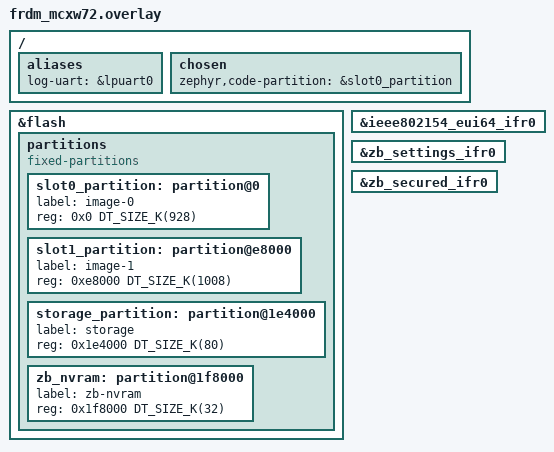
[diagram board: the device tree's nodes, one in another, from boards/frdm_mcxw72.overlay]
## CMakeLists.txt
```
# SPDX-License-Identifier: Apache-2.0

cmake_minimum_required(VERSION 3.20.0)

# Add cli feature config fragment
get_filename_component(ZBOSS_CONFIG_DIR ${CMAKE_CURRENT_SOURCE_DIR}/../../config REALPATH)
set(EXTRA_CONF_FILE ${ZBOSS_CONFIG_DIR}/add_cli.conf)

# CLI zed     : west build -b frdm_rw612 modules/zboss/samples/cli_nxp -d _build/frdm_rw612/cli_nxp_zed  -p -- -DDEVICE_TYPE=zed
# CLI zczr    : west build -b frdm_rw612 modules/zboss/samples/cli_nxp -d _build/frdm_rw612/cli_nxp_zczr -p -- -DDEVICE_TYPE=zczr
# Please note : both application can not be built at the same time in the same folder

set(DEVICE_TYPE "zed" CACHE STRING "Device type: zed or zczr")

if(DEVICE_TYPE STREQUAL "zed")
    set(OVERLAY_CONFIG ${CMAKE_CURRENT_SOURCE_DIR}/conf/zed.conf)
elseif(DEVICE_TYPE STREQUAL "zczr")
    set(OVERLAY_CONFIG ${CMAKE_CURRENT_SOURCE_DIR}/conf/zczr.conf)
else()
    message(FATAL_ERROR "Unsupported DEVICE_TYPE '${DEVICE_TYPE}' (expected 'zed' or 'zczr').")
endif()

message(STATUS "cli_nxp: building for DEVICE_TYPE '${DEVICE_TYPE}'")

find_package(Zephyr REQUIRED HINTS $ENV{ZEPHYR_BASE})
project(cli_nxp)

target_sources(app PRIVATE
	       src/cli_main.c
	       src/cli_network.c
	       src/cli_endpoint.c
	       src/cli_cluster.c
	       src/cli_zdo.c
	       src/cli_installcode.c
	       src/cli_nvram.c
	       src/cli_tcso.c
	       src/cli_tools.c
	       src/cli_config.c
	       src/cli_menu_console.c
	       )
```

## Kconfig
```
# Copyright 2024-2025 NXP
# SPDX-License-Identifier: Apache-2.0

source "Kconfig.zephyr"
module = ZBOSS_APPLICATION
module-str = zboss_main
source "${ZEPHYR_BASE}/subsys/logging/Kconfig.template.log_config"
```

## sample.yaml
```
sample:
  name: cli_nxp
  description: >
    sample application demonstrating Zigbee functionality for NXP ZBOSS stack
  common:
    min_ram: 32
    min_flash: 256
    tags: zboss
    depends_on: zboss

tests:
  sample.zboss.basic:
    tags: zboss
    harness: console
    harness_config:
      type: one_line
      regex:
        - "Zboss (.*)"
    platform_allow:
      - frdm_mcxw71
      - frdm_mcxw72
      - frdm_rw612
```

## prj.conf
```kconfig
# Zigbee Zboss Application

# OS
CONFIG_EVENTS=y
CONFIG_HEAP_MEM_POOL_SIZE=16384
CONFIG_MAIN_STACK_SIZE=6144
# Must be higher that MAC_INTF_CB_TASK_PRIORITY, refer to:
# modules/hal/nxp/mcux/middleware/mcux-sdk-middleware-ieee_802.15.4/ieee_802_15_4/mac/source/App/mac_intf_rpmsg.c
CONFIG_MAIN_THREAD_PRIORITY=5

# Enable NVMEM subsystem
CONFIG_NVMEM=y
CONFIG_NVMEM_FLASH=y
#CONFIG_LOG=y
#CONFIG_NVMEM_LOG_LEVEL_DBG=y

# Flash
CONFIG_FLASH=y
CONFIG_FLASH_MAP=y
CONFIG_FLASH_PAGE_LAYOUT=y

CONFIG_NVS=y
#CONFIG_LOG=y
#CONFIG_NVS_LOG_LEVEL_DBG=y

CONFIG_TEST_RANDOM_GENERATOR=y

CONFIG_REBOOT=y
CONFIG_ASSERT=y

CONFIG_NXP_RF_IMU=y
CONFIG_NXP_IEEE802154_MAC=y

CONFIG_DEBUG=y

CONFIG_FPU=y
CONFIG_FP_HARDABI=y

# ZBOSS module
CONFIG_ZBOSS=y
CONFIG_ZBOSS_LOGS_ON_UART=n

CONFIG_ENTROPY_GENERATOR=y
CONFIG_ENTROPY_NXP_ELE_TRNG=y

# End of common configs 
```

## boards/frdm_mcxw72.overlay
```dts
/*
 * Copyright 2026 NXP
 * SPDX-License-Identifier: Apache-2.0
 */

/ {
	aliases {
		log-uart = &lpuart0;
	};
};

/ {
	chosen {
		zephyr,code-partition = &slot0_partition;
	};
};

/* Delete all existing partitions */
/delete-node/ &boot_partition;
/delete-node/ &slot0_partition;
/delete-node/ &slot1_partition;
/delete-node/ &storage_partition;

/* Redefine internal flash partitions */
&flash {
	/delete-node/ partitions;

	partitions {
		compatible = "fixed-partitions";
		#address-cells = <1>;
		#size-cells = <1>;

		slot0_partition: partition@0 {
			label = "image-0";
			reg = <0x0 DT_SIZE_K(928)>;
		};

		/*
		 * slot1 is a bit larger than slot0 to account
		 * for the overhead introduced by SB3.1 format.
		 */
		slot1_partition: partition@e8000 {
			label = "image-1";
			reg = <0xe8000 DT_SIZE_K(1008)>;
		};

		storage_partition: partition@1e4000 {
			label = "storage";
			reg = <0x1e4000 DT_SIZE_K(80)>;
		};

		zb_nvram: partition@1f8000 {
			label = "zb-nvram";
			reg = <0x1f8000 DT_SIZE_K(32)>;
		};
	};
};

&ieee802154_eui64_ifr0 {
	status = "okay";
};

&zb_settings_ifr0 {
	status = "okay";
};

&zb_secured_ifr0 {
	status = "okay";
};
```

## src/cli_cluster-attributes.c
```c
/*
 * Copyright 2024-2026 NXP
 *
 * NXP Proprietary.
 * This software is owned or controlled by NXP and may only be used strictly
 * in accordance with the applicable license terms. By expressly accepting
 * such terms or by downloading, installing, activating and/or otherwise using
 * the software, you are agreeing that you have read, and that you agree to
 * comply with and are bound by, such license terms. If you do not agree to be
 * bound by the applicable license terms, then you may not retain, install,
 * activate or otherwise use the software.
 *
 */


static void menu_print_cluster_attributes(zb_zcl_device_callback_param_t *device_cb_params, zb_af_endpoint_desc_t *this_ep)
{
  menu_printf("Callback endpoint %u(%d clusters), attr %d, %s",
    device_cb_params->endpoint,
    (this_ep)?(this_ep->cluster_count):(0),
    device_cb_params->attr_type,
    get_device_cb_id_str(device_cb_params->device_cb_id));

}

#if defined(CLI_HAS_CLUSTER_OTA_UPGRADE_CLT) || defined(CLI_HAS_CLUSTER_OTA_UPGRADE_SRV) || defined(CLI_HAS_CLUSTER_SCENES)
static zb_bool_t is_cluster_created(zb_af_endpoint_desc_t *this_ep, zb_uint16_t cluster_id, zb_uint8_t role)
{
  if(!this_ep)
    return ZB_FALSE;

  for(int i=0; i<this_ep->cluster_count; i++)
    if(this_ep->cluster_desc_list[i].cluster_id == cluster_id &&
       this_ep->cluster_desc_list[i].role_mask & role)
      return ZB_TRUE;

  return ZB_FALSE;
}
#endif /* CLI_HAS_CLUSTER_OTA_UPGRADE_CLT || CLI_HAS_CLUSTER_OTA_UPGRADE_SRV || CLI_HAS_CLUSTER_SCENES */

void cluster_attributes_cb(zb_uint8_t param)
{
  zb_zcl_device_callback_param_t *device_cb_params = ZB_BUF_GET_PARAM(param, zb_zcl_device_callback_param_t);
  zb_af_endpoint_desc_t *this_ep = endpoint_get_by_id(device_cb_params->endpoint);

  device_cb_params->status = RET_NOT_IMPLEMENTED; //Will return ZCL status ZB_ZCL_STATUS_UNSUP_CMD
  switch(device_cb_params->device_cb_id)
  {
#ifdef CLI_HAS_CLUSTER_OTA_UPGRADE_CLT
  case ZB_ZCL_OTA_UPGRADE_VALUE_CB_ID:
    // done inside the handler... menu_print_cluster_attributes(device_cb_params, this_ep);
    /* Make sure we have created the ota cluster on client side */
    if(is_cluster_created(this_ep, ZB_ZCL_CLUSTER_ID_OTA_UPGRADE, ZB_ZCL_CLUSTER_CLIENT_ROLE))
    {
      device_cb_params->status = cluster_ota_clt_device_value_cb(device_cb_params);
    }
    else
    {
      device_cb_params->status = RET_INVALID_PARAMETER;
    }
    break;
#endif /* CLI_HAS_CLUSTER_OTA_UPGRADE_CLT */

#ifdef CLI_HAS_CLUSTER_OTA_UPGRADE_SRV
  case ZB_ZCL_OTA_UPGRADE_SRV_QUERY_IMAGE_CB_ID:
    menu_print_cluster_attributes(device_cb_params, this_ep);
    /* Make sure we have created the ota cluster on client side */
    if(is_cluster_created(this_ep, ZB_ZCL_CLUSTER_ID_OTA_UPGRADE, ZB_ZCL_CLUSTER_SERVER_ROLE))
    {
      /* Well we have already inserted files to the stack, let it manage it */
      device_cb_params->status = RET_NOT_FOUND;
    }
    else
    {
      device_cb_params->status = RET_INVALID_PARAMETER;
    }
    break;
#endif /* CLI_HAS_CLUSTER_OTA_UPGRADE_SRV */

  case ZB_ZCL_SET_ATTR_VALUE_CB_ID:
    /* This case has been added to avoid going into the default case which returns an error code, when we have a set attribute command. */
    device_cb_params->status = RET_OK;
    break;

#ifdef CLI_HAS_CLUSTER_SCENES
  case ZB_ZCL_SCENES_ADD_SCENE_CB_ID:
  case ZB_ZCL_SCENES_STORE_SCENE_CB_ID:
  case ZB_ZCL_SCENES_VIEW_SCENE_CB_ID:
  case ZB_ZCL_SCENES_REMOVE_SCENE_CB_ID:
  case ZB_ZCL_SCENES_REMOVE_ALL_SCENES_CB_ID:
  case ZB_ZCL_SCENES_RECALL_SCENE_CB_ID:
  case ZB_ZCL_SCENES_GET_SCENE_MEMBERSHIP_CB_ID:
#ifndef ZB_ZCL_SCENES_OPTIONAL_COMMANDS_DISABLED
  case ZB_ZCL_SCENES_ENHANCED_ADD_SCENE_CB_ID:
  case ZB_ZCL_SCENES_ENHANCED_VIEW_SCENE_CB_ID:
  case ZB_ZCL_SCENES_COPY_SCENE_CB_ID:
#endif /* !ZB_ZCL_SCENES_OPTIONAL_COMMANDS_DISABLED */
    if(is_cluster_created(this_ep, ZB_ZCL_CLUSTER_ID_SCENES, ZB_ZCL_CLUSTER_SERVER_ROLE))
    {
      device_cb_params->status = cluster_scenes_srv_device_value_cb(device_cb_params, param);
    }
    else
    {
      zb_uint8_t *add_scene_status = ZB_ZCL_DEVICE_CMD_PARAM_OUT_GET(param, zb_uint8_t);
      *add_scene_status = ZB_ZCL_STATUS_UNSUP_CLUST_CMD;
      device_cb_params->status = RET_NOT_IMPLEMENTED;
    }
    break;

  case ZB_ZCL_SCENES_INTERNAL_REMOVE_ALL_SCENES_ALL_ENDPOINTS_ALL_GROUPS_CB_ID:
  case ZB_ZCL_SCENES_INTERNAL_REMOVE_ALL_SCENES_ALL_ENDPOINTS_CB_ID:
    {
      /* Internal: indicate to application that it is needed to remove all scenes on all
       * endpoints for XXX groups (full reset of scenes table if XXX is all).
       */
      for(int i=0; i<256; i++)
      {
        this_ep = endpoint_get_by_id(i);
        if(!this_ep)
          continue;

        if(is_cluster_created(this_ep, ZB_ZCL_CLUSTER_ID_SCENES, ZB_ZCL_CLUSTER_SERVER_ROLE))
        {
          device_cb_params->endpoint = i;
          cluster_scenes_srv_device_value_cb(device_cb_params, param);
        }
      }
      device_cb_params->status = RET_OK;
    }
    break;
#endif /* CLI_HAS_CLUSTER_SCENES */
#ifdef CLI_HAS_CLUSTER_POLL_CONTROL
  case ZB_ZCL_POLL_CONTROL_CHECK_IN_CLI_CB_ID:
    {
      /* Enable fast polling after Check-in */
      device_cb_params->status = cluster_poll_control_device_value_cb(device_cb_params, param);
    }
    break;
#endif

  default:
    menu_print_cluster_attributes(device_cb_params, this_ep);
    break;
  }

  menu_cb_occured();
}


int wcs_snprintf_attr_raw(char *str, size_t size, zb_uint8_t type, zb_uint8_t *value)
{
  int len = 0;
  zb_uint8_t attr_len = zb_zcl_get_attribute_size(type, value);

  if(!str || !attr_len)
    return len;

  for(zb_uint8_t i=0; i<attr_len; i++)
    len += wcs_snprintf(str+len, size-len, "%02x:", value[i]);

  /* Remove last ":" */
  str[len-1] = '\0';

  return len-1;
}


typedef union {
  zb_bool_t   boolean;
  zb_uint8_t  u8;
  zb_uint16_t u16;
  zb_uint32_t u32;
  zb_uint64_t u64;
  zb_int8_t   s8;
  zb_int16_t  s16;
  zb_int32_t  s32;
  zb_int64_t  s64;
} cast_t;
#ifdef ZB_LITTLE_ENDIAN

  #define ENDIAN_24_TO_32(val8,val32) val32 = 0;                                                                            \
    val32 =              val8[3]; val32 = (val32<<8) + val8[2]; val32 = (val32<<8) + val8[1]; val32 = (val32<<8) + val8[0];

  #define ENDIAN_40_TO_64(val8,val64) val64 = 0;                                                                            \
                                                                                              val64 = (val64<<8) + val8[4]; \
    val64 = (val64<<8) + val8[3]; val64 = (val64<<8) + val8[2]; val64 = (val64<<8) + val8[1]; val64 = (val64<<8) + val8[0];

  #define ENDIAN_48_TO_64(val8,val64) val64 = 0;                                                                            \
                                                                val64 = (val64<<8) + val8[5]; val64 = (val64<<8) + val8[4]; \
    val64 = (val64<<8) + val8[3]; val64 = (val64<<8) + val8[2]; val64 = (val64<<8) + val8[1]; val64 = (val64<<8) + val8[0];

  #define ENDIAN_56_TO_64(val8,val64) val64 = 0;                                                                            \
                                  val64 = (val64<<8) + val8[6]; val64 = (val64<<8) + val8[5]; val64 = (val64<<8) + val8[4]; \
    val64 = (val64<<8) + val8[3]; val64 = (val64<<8) + val8[2]; val64 = (val64<<8) + val8[1]; val64 = (val64<<8) + val8[0];

#else

  #define ENDIAN_24_TO_32(val8,val32) val32 = 0;                                                                            \
    val32 = (val32<<8) + val8[0]; val32 = (val32<<8) + val8[1]; val32 = (val32<<8) + val8[2];

  #define ENDIAN_40_TO_64(val8,val64) val64 = 0;                                                                            \
    val64 = (val64<<8) + val8[0]; val64 = (val64<<8) + val8[1]; val64 = (val64<<8) + val8[2]; val64 = (val64<<8) + val8[3]; \
    val64 = (val64<<8) + val8[4];

  #define ENDIAN_48_TO_64(val8,val64) val64 = 0;                                                                            \
    val64 = (val64<<8) + val8[0]; val64 = (val64<<8) + val8[1]; val64 = (val64<<8) + val8[2]; val64 = (val64<<8) + val8[3]; \
    val64 = (val64<<8) + val8[4]; val64 = (val64<<8) + val8[5];

  #define ENDIAN_56_TO_64(val8,val64) val64 = 0;                                                                            \
    val64 = (val64<<8) + val8[0]; val64 = (val64<<8) + val8[1]; val64 = (val64<<8) + val8[2]; val64 = (val64<<8) + val8[3]; \
    val64 = (val64<<8) + val8[4]; val64 = (val64<<8) + val8[5]; val64 = (val64<<8) + val8[6];

#endif

int wcs_snprintf_attr_val(char *str, size_t size, zb_uint8_t type, zb_uint8_t *value)
{
  int len = 0;
  zb_uint8_t attr_len = zb_zcl_get_attribute_size(type, value);
  cast_t *cast_val = (cast_t *)value;
  cast_t data_val;

  if(!str)
    return len;

  switch(type) {
  case ZB_ZCL_ATTR_TYPE_NULL:              /*!<  0x00U: Null data type */
    len += wcs_snprintf(str+len, size-len, "NULL ");
    break;
  case ZB_ZCL_ATTR_TYPE_BOOL:              /*!<  0x10U: Boolean data type */
    len += wcs_snprintf(str+len, size-len, "%s ", (cast_val->boolean)?("true"):("false"));
    break;
  case ZB_ZCL_ATTR_TYPE_8BIT:              /*!<  0x08U: 8-bit value data type */
  case ZB_ZCL_ATTR_TYPE_8BITMAP:           /*!<  0x18U: 8-bit bitmap data type */
    len += wcs_snprintf(str+len, size-len, "0x%02x ", cast_val->u8);
    break;
  case ZB_ZCL_ATTR_TYPE_U8:                /*!<  0x20U: Unsigned 8-bit value data type */
  case ZB_ZCL_ATTR_TYPE_8BIT_ENUM:         /*!<  0x30U: 8-bit enumeration (U8 discrete) data type */
    len += wcs_snprintf(str+len, size-len, "%hhu ", cast_val->u8);
    break;
  case ZB_ZCL_ATTR_TYPE_S8:                /*!<  0x28U: Signed 8-bit value data type */
    len += wcs_snprintf(str+len, size-len, "%hhd ", cast_val->s8);
    break;
  case ZB_ZCL_ATTR_TYPE_16BIT:             /*!<  0x09U: 16-bit value data type */
  case ZB_ZCL_ATTR_TYPE_16BITMAP:          /*!<  0x19U: 16-bit bitmap data type */
    len += wcs_snprintf(str+len, size-len, "0x%04x ", cast_val->u16);
    break;
  case ZB_ZCL_ATTR_TYPE_U16:               /*!<  0x21U: Unsigned 16-bit value data type */
  case ZB_ZCL_ATTR_TYPE_16BIT_ENUM:        /*!<  0x31U: 16-bit enumeration (U16 discrete) data type */
    len += wcs_snprintf(str+len, size-len, "%hu ", cast_val->u16);
    break;
  case ZB_ZCL_ATTR_TYPE_S16:               /*!<  0x29U: Signed 16-bit value data type */
    len += wcs_snprintf(str+len, size-len, "%hd ", cast_val->s16);
    break;
  case ZB_ZCL_ATTR_TYPE_24BIT:             /*!<  0x0aU: 24-bit value data type */
  case ZB_ZCL_ATTR_TYPE_24BITMAP:          /*!<  0x1aU: 24-bit bitmap data type */
    ENDIAN_24_TO_32(value, data_val.u32);
    len += wcs_snprintf(str+len, size-len, "0x%06x ", data_val.u32);
    break;
  case ZB_ZCL_ATTR_TYPE_U24:               /*!<  0x22U: Unsigned 24-bit value data type */
    ENDIAN_24_TO_32(value, data_val.u32);
    len += wcs_snprintf(str+len, size-len, "%hu ", data_val.u32);
    break;
// TODO  case ZB_ZCL_ATTR_TYPE_S24:               /*!<  0x2aU: Signed 24-bit value data type */
    break;
  case ZB_ZCL_ATTR_TYPE_32BIT:             /*!<  0x0bU: 32-bit value data type */
  case ZB_ZCL_ATTR_TYPE_32BITMAP:          /*!<  0x1bU: 32-bit bitmap data type */
    len += wcs_snprintf(str+len, size-len, "0x%08x ", cast_val->u32);
    break;
  case ZB_ZCL_ATTR_TYPE_U32:               /*!<  0x23U: Unsigned 32-bit value data type */
    len += wcs_snprintf(str+len, size-len, "%u ", cast_val->u32);
    break;
  case ZB_ZCL_ATTR_TYPE_S32:               /*!<  0x2bU: Signed 32-bit value data type */
    len += wcs_snprintf(str+len, size-len, "%d ", cast_val->s32);
    break;
  case ZB_ZCL_ATTR_TYPE_40BIT:             /*!<  0x0cU: 40-bit value data type */
  case ZB_ZCL_ATTR_TYPE_40BITMAP:          /*!<  0x1cU: 40-bit bitmap data type */
    ENDIAN_40_TO_64(value, data_val.u64);
    len += wcs_snprintf(str+len, size-len, "0x%10lx ", data_val.u64);
    break;
  case ZB_ZCL_ATTR_TYPE_U40:               /*!<  0x24U: Unsigned 40-bit value data type */
    ENDIAN_40_TO_64(value, data_val.u64);
    len += wcs_snprintf(str+len, size-len, "%lu ", data_val.u64);
    break;
// TODO  case ZB_ZCL_ATTR_TYPE_S40:               /*!<  0x2cU: Signed 40-bit value data type */
    break;
  case ZB_ZCL_ATTR_TYPE_48BIT:             /*!<  0x0dU: 48-bit value data type */
  case ZB_ZCL_ATTR_TYPE_48BITMAP:          /*!<  0x1dU: 48-bit bitmap data type */
    ENDIAN_48_TO_64(value, data_val.u64);
    len += wcs_snprintf(str+len, size-len, "0x%12lx ", data_val.u64);
    break;
  case ZB_ZCL_ATTR_TYPE_U48:               /*!<  0x25U: Unsigned 48-bit value data type */
    ENDIAN_48_TO_64(value, data_val.u64);
    len += wcs_snprintf(str+len, size-len, "%lu ", data_val.u64);
    break;
// TODO  case ZB_ZCL_ATTR_TYPE_S48:               /*!<  0x2dU: Signed 48-bit value data type */
    break;
  case ZB_ZCL_ATTR_TYPE_56BIT:             /*!<  0x0eU: 56-bit value data type */
  case ZB_ZCL_ATTR_TYPE_56BITMAP:          /*!<  0x1eU: 56-bit bitmap data type */
    ENDIAN_56_TO_64(value, data_val.u64);
    len += wcs_snprintf(str+len, size-len, "0x%14lx ", data_val.u64);
    break;
  case ZB_ZCL_ATTR_TYPE_U56:               /*!<  0x26U: Unsigned 56-bit value data type */
    ENDIAN_56_TO_64(value, data_val.u64);
    len += wcs_snprintf(str+len, size-len, "%lu ", data_val.u64);
    break;
// TODO  case ZB_ZCL_ATTR_TYPE_S56:               /*!<  0x2eU: Signed 56-bit value data type */
    break;
  case ZB_ZCL_ATTR_TYPE_64BIT:             /*!<  0x0fU: 64-bit value data type */
  case ZB_ZCL_ATTR_TYPE_64BITMAP:          /*!<  0x1fU: 64-bit bitmap data type */
    len += wcs_snprintf(str+len, size-len, "0x%16lx ", cast_val->u64);
    break;
  case ZB_ZCL_ATTR_TYPE_U64:               /*!<  0x27U: Unsigned 64-bit value data type */
    len += wcs_snprintf(str+len, size-len, "%lu ", cast_val->u64);
    break;
  case ZB_ZCL_ATTR_TYPE_S64:               /*!<  0x2bU: Signed 32-bit value data type */
    len += wcs_snprintf(str+len, size-len, "%ld ", cast_val->s64);
    break;

// TODO  case ZB_ZCL_ATTR_TYPE_SEMI:              /*!<  0x38U: 2 byte floating point */
    break;
// TODO  case ZB_ZCL_ATTR_TYPE_SINGLE:            /*!<  0x39U: 4 byte floating point */
    break;
// TODO  case ZB_ZCL_ATTR_TYPE_DOUBLE:            /*!<  0x3aU: 8 byte floating point */
    break;
// TODO  case ZB_ZCL_ATTR_TYPE_OCTET_STRING:      /*!<  0x41U: Octet string data type */
    break;
  case ZB_ZCL_ATTR_TYPE_CHAR_STRING:       /*!<  0x42U: Character string (array) data type */
    for(int i=1; i<value[0]; i++)
      len += wcs_snprintf(str+len, size-len, "%c", value[i]);
    len += wcs_snprintf(str+len, size-len, " ");
    break;
// TODO  case ZB_ZCL_ATTR_TYPE_LONG_OCTET_STRING: /*!<  0x43U: Long octet string */
    break;
// TODO  case ZB_ZCL_ATTR_TYPE_LONG_CHAR_STRING:  /*!<  0x44U: Long character string */
    break;
// TODO  case ZB_ZCL_ATTR_TYPE_ARRAY:             /*!<  0x48U: Array data type 2 + sum of content len */
    break;
// TODO  case ZB_ZCL_ATTR_TYPE_STRUCTURE:         /*!<  0x4cU: Structure data type 2 + sum of content len */
    break;
// TODO  case ZB_ZCL_ATTR_TYPE_SET:               /*!<  0x50U: Collection:set, size = sum of len of content */
    break;
// TODO  case ZB_ZCL_ATTR_TYPE_BAG:               /*!<  0x51U: Collection:bag, size = sum of len of content */
    break;
  case ZB_ZCL_ATTR_TYPE_TIME_OF_DAY:       /*!<  0xe0U: Time of day, 4 bytes */
    len += wcs_snprintf(str+len, size-len, "0x%08x ", cast_val->u32);
    break;
  case ZB_ZCL_ATTR_TYPE_DATE:              /*!<  0xe1U: Date, 4 bytes */
    len += wcs_snprintf(str+len, size-len, "0x%08x ", cast_val->u32);
    break;
  case ZB_ZCL_ATTR_TYPE_UTC_TIME:          /*!<  0xe2U: UTC Time, 4 bytes */
    len += wcs_snprintf(str+len, size-len, "0x%08x ", cast_val->u32);
    break;
  case ZB_ZCL_ATTR_TYPE_CLUSTER_ID:        /*!<  0xe8U: Cluster ID, 2 bytes */
    len += wcs_snprintf(str+len, size-len, "0x%04x ", cast_val->u16);
    break;
  case ZB_ZCL_ATTR_TYPE_ATTRIBUTE_ID:      /*!<  0xe9U: Attribute ID, 2 bytes */
    len += wcs_snprintf(str+len, size-len, "0x%04x ", cast_val->u16);
    break;
  case ZB_ZCL_ATTR_TYPE_BACNET_OID:        /*!<  0xeaU: BACnet OID, 4 bytes */
    len += wcs_snprintf(str+len, size-len, "0x%08x ", cast_val->u32);
    break;
  case ZB_ZCL_ATTR_TYPE_IEEE_ADDR:
    len += wcs_snprintf(str+len, size-len, TRACE_FORMAT_64, TRACE_ARG_64(value));
    break;
  case ZB_ZCL_ATTR_TYPE_128_BIT_KEY:
    len += wcs_snprintf(str+len, size-len, TRACE_FORMAT_128, TRACE_ARG_128(value));
    break;

  default:
    len += wcs_snprintf(str+len, size-len, "Type:0x%02x,Len:%u", type, attr_len);
    break;
  }
  return len;
}
```

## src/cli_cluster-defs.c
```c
/*
 * Copyright 2024-2026 NXP
 *
 * NXP Proprietary.
 * This software is owned or controlled by NXP and may only be used strictly
 * in accordance with the applicable license terms. By expressly accepting
 * such terms or by downloading, installing, activating and/or otherwise using
 * the software, you are agreeing that you have read, and that you agree to
 * comply with and are bound by, such license terms. If you do not agree to be
 * bound by the applicable license terms, then you may not retain, install,
 * activate or otherwise use the software.
 *
 */


#ifdef CLI_HAS_CLUSTER_BASIC
/* -----------------------------------------------------------------------------------
 *
 *                                  CLUSTER Basic
 *
 * ----------------------------------------------------------------------------------- */

/* Basic cluster attributes */
typedef struct {
  /* ZCL version attribute */
  zb_uint8_t zcl_version;
  /* Power source attribute */
  zb_uint8_t power_source;
} zb_zcl_general_basic_attr_t;

static zb_zcl_general_basic_attr_t g_general_basic_attr = {
  .zcl_version  = ZB_ZCL_VERSION,
  .power_source = ZB_ZCL_BASIC_POWER_SOURCE_UNKNOWN,
};
#endif /* CLI_HAS_CLUSTER_BASIC */

/* -----------------------------------------------------------------------------------
 *
 *                                  CLUSTER Power Configuration
 *
 * ----------------------------------------------------------------------------------- */


/* -----------------------------------------------------------------------------------
 *
 *                                  CLUSTER Device Temperature Configuration
 *
 * ----------------------------------------------------------------------------------- */


#ifdef CLI_HAS_CLUSTER_IDENTITY
/* -----------------------------------------------------------------------------------
 *
 *                                  CLUSTER Identify
 *
 * ----------------------------------------------------------------------------------- */

/* Identify cluster attributes */
typedef struct {
  zb_uint16_t identify_time;
} zb_zcl_general_identity_attr_t;

static zb_zcl_general_identity_attr_t g_general_identity_attr = {
  .identify_time = ZB_ZCL_IDENTIFY_IDENTIFY_TIME_DEFAULT_VALUE,
};
#endif /* CLI_HAS_CLUSTER_IDENTITY */


#ifdef CLI_HAS_CLUSTER_GROUPS
/* -----------------------------------------------------------------------------------
 *
 *                                  CLUSTER Groups
 *
 * ----------------------------------------------------------------------------------- */

/* Groups cluster attributes */
typedef struct {
  zb_uint8_t name_support;
} zb_zcl_general_groups_attr_t;

static zb_zcl_general_groups_attr_t g_general_groups_attr = {
  .name_support = 0,
};
#endif /* CLI_HAS_CLUSTER_GROUPS */


#ifdef CLI_HAS_CLUSTER_SCENES
/* -----------------------------------------------------------------------------------
 *
 *                                  CLUSTER Scenes
 *
 * ----------------------------------------------------------------------------------- */

/* Scenes cluster attributes */
typedef struct {
  zb_uint8_t  scene_count;
  zb_uint8_t  current_scene;
  zb_uint16_t current_group;
  zb_uint8_t  scene_valid;
  zb_uint16_t name_support;
} zb_zcl_general_scenes_attr_t;

static zb_zcl_general_scenes_attr_t g_general_scenes_attr = {
  .scene_count   = ZB_ZCL_SCENES_SCENE_COUNT_DEFAULT_VALUE,
  .current_scene = ZB_ZCL_SCENES_CURRENT_SCENE_DEFAULT_VALUE,
  .current_group = ZB_ZCL_SCENES_CURRENT_GROUP_DEFAULT_VALUE,
  .scene_valid   = ZB_ZCL_SCENES_SCENE_VALID_DEFAULT_VALUE,
  .name_support  = ZB_ZCL_SCENES_NAME_SUPPORT_DEFAULT_VALUE,
};
#endif /* CLI_HAS_CLUSTER_SCENES */


#ifdef CLI_HAS_CLUSTER_ONOFF
/* -----------------------------------------------------------------------------------
 *
 *                                  CLUSTER ON/OFF
 *
 * ----------------------------------------------------------------------------------- */


/* On/Off cluster attributes */
typedef struct {
  zb_uint8_t on_off;
} zb_zcl_general_on_off_attr_t;

static zb_zcl_general_on_off_attr_t g_general_on_off_attr = {
  .on_off = ZB_ZCL_ON_OFF_ON_OFF_DEFAULT_VALUE,
};
#endif /* CLI_HAS_CLUSTER_ONOFF */


#ifdef CLI_HAS_CLUSTER_ONOFF_SWITCH
/* -----------------------------------------------------------------------------------
 *
 *                                  CLUSTER ON/OFF Switch Configuration
 *
 * ----------------------------------------------------------------------------------- */

/* Switch config cluster attributes */
typedef struct {
  zb_uint8_t type;
  zb_uint8_t actions;
} zb_zcl_general_on_off_switch_attr_t;

static zb_zcl_general_on_off_switch_attr_t g_general_on_off_switch_attr = {
  .type    = ZB_ZCL_ON_OFF_SWITCH_CONFIGURATION_SWITCH_TYPE_TOGGLE,
  .actions = ZB_ZCL_ON_OFF_SWITCH_CONFIGURATION_SWITCH_ACTIONS_DEFAULT_VALUE,
};
#endif /* CLI_HAS_CLUSTER_ONOFF_SWITCH */


/* -----------------------------------------------------------------------------------
 *
 *                                  CLUSTER Level Control
 *
 * ----------------------------------------------------------------------------------- */


/* -----------------------------------------------------------------------------------
 *
 *                                  CLUSTER Alarms
 *
 * ----------------------------------------------------------------------------------- */


/* -----------------------------------------------------------------------------------
 *
 *                                  CLUSTER Time
 *
 * ----------------------------------------------------------------------------------- */


/* -----------------------------------------------------------------------------------
 *
 *                                  CLUSTER RSSI Location
 *
 * ----------------------------------------------------------------------------------- */


/* -----------------------------------------------------------------------------------
 *
 *                                  CLUSTER Analog Input
 *
 * ----------------------------------------------------------------------------------- */


/* -----------------------------------------------------------------------------------
 *
 *                                  CLUSTER Analog Output
 *
 * ----------------------------------------------------------------------------------- */


/* -----------------------------------------------------------------------------------
 *
 *                                  CLUSTER Analogue Value
 *
 * ----------------------------------------------------------------------------------- */


/* -----------------------------------------------------------------------------------
 *
 *                                  CLUSTER Binary Input
 *
 * ----------------------------------------------------------------------------------- */


/* -----------------------------------------------------------------------------------
 *
 *                                  CLUSTER Binary Output
 *
 * ----------------------------------------------------------------------------------- */


/* -----------------------------------------------------------------------------------
 *
 *                                  CLUSTER Binary Value
 *
 * ----------------------------------------------------------------------------------- */


/* -----------------------------------------------------------------------------------
 *
 *                                  CLUSTER Multistate Input
 *
 * ----------------------------------------------------------------------------------- */


/* -----------------------------------------------------------------------------------
 *
 *                                  CLUSTER Multistate Output
 *
 * ----------------------------------------------------------------------------------- */


/* -----------------------------------------------------------------------------------
 *
 *                                  CLUSTER Multistate Value
 *
 * ----------------------------------------------------------------------------------- */


/* -----------------------------------------------------------------------------------
 *
 *                                  CLUSTER Diagnostics
 *
 * ----------------------------------------------------------------------------------- */


/* -----------------------------------------------------------------------------------
 *
 *                                  CLUSTER Poll Control
 *
 * ----------------------------------------------------------------------------------- */

/* Poll Control cluster attributes */

#define ZB_ZCL_POLL_CONTROL_NXP_MIN_CHECKIN_INTERVAL         0x10  /* 16 quarterseconds == 4 sec  */
#define ZB_ZCL_POLL_CONTROL_NXP_CHECKIN_INTERVAL             0x50  /* 80 quarterseconds == 20 sec */
#define ZB_ZCL_POLL_CONTROL_NXP_MIN_LONG_POLL_INTERVAL      4
#define ZB_ZCL_POLL_CONTROL_NXP_FAST_POLL_MAX_TIMEOUT_DEFAULT_VALUE 300 /* 300 quarterseconds == 75 seconds */

typedef struct zb_zcl_general_poll_control_attr_s
{
  zb_uint32_t checkin_interval;
  zb_uint32_t long_poll_interval;
  zb_uint16_t short_poll_interval;
  zb_uint16_t fast_poll_timeout;
  zb_uint32_t checkin_interval_min;
  zb_uint32_t long_poll_interval_min;
  zb_uint16_t fast_poll_timeout_max;
}
zb_zcl_general_poll_control_attr_t;

static zb_zcl_general_poll_control_attr_t g_general_poll_control_attr = {
  .checkin_interval       = ZB_ZCL_POLL_CONTROL_NXP_CHECKIN_INTERVAL,
  .long_poll_interval     = ZB_ZCL_POLL_CONTROL_LONG_POLL_INTERVAL_DEFAULT_VALUE,
  .short_poll_interval    = ZB_ZCL_POLL_CONTROL_SHORT_POLL_INTERVAL_DEFAULT_VALUE,
  .fast_poll_timeout      = ZB_ZCL_POLL_CONTROL_FAST_POLL_TIMEOUT_DEFAULT_VALUE,
  .checkin_interval_min   = ZB_ZCL_POLL_CONTROL_NXP_MIN_CHECKIN_INTERVAL,
  .long_poll_interval_min = ZB_ZCL_POLL_CONTROL_NXP_MIN_LONG_POLL_INTERVAL,
  .fast_poll_timeout_max  = ZB_ZCL_POLL_CONTROL_NXP_FAST_POLL_MAX_TIMEOUT_DEFAULT_VALUE,
};

static zb_zcl_poll_control_client_status_t pollctrl_client_status = {
  .is_poll_mode      = ZB_TRUE,
  .fast_poll_timeout = ZB_ZCL_POLL_CONTROL_FAST_POLL_TIMEOUT_DEFAULT_VALUE,
};

static zb_zcl_poll_control_srv_cfg_data_t pollctrl_srv_cfg_data = {
  .poll_addr      = ZB_ZCL_POLL_CTRL_INVALID_ADDR,
  .poll_ep        = ZB_ZCL_POLL_INVALID_EP,
  .sending_cmd    = 0,
  .fast_poll_mode = 0,
};


/* -----------------------------------------------------------------------------------
 *
 *                                  CLUSTER Power Profile
 *
 * ----------------------------------------------------------------------------------- */


/* -----------------------------------------------------------------------------------
 *
 *                                  CLUSTER Meter Identification
 *
 * ----------------------------------------------------------------------------------- */


/* -----------------------------------------------------------------------------------
 *
 *                                  CLUSTER Illuminance Measurement
 *
 * ----------------------------------------------------------------------------------- */


/* -----------------------------------------------------------------------------------
 *
 *                                  CLUSTER Illuminance Level Sensing
 *
 * ----------------------------------------------------------------------------------- */


#ifdef CLI_HAS_CLUSTER_TEMPERATURE
/* -----------------------------------------------------------------------------------
 *
 *                                  CLUSTER Temperature Measurement
 *
 * ----------------------------------------------------------------------------------- */

/* On/Off cluster attributes */
typedef struct {
  zb_int16_t value;
  zb_int16_t min_value;
  zb_int16_t max_value;
  zb_uint16_t tolerance;
} zb_zcl_measur_lvlsensor_temp_measurement_attr_t;

static zb_zcl_measur_lvlsensor_temp_measurement_attr_t g_lvlsensor_temp_measurement_attr = {
  .value = ZB_ZCL_TEMP_MEASUREMENT_VALUE_DEFAULT_VALUE,
  .min_value = ZB_ZCL_TEMP_MEASUREMENT_MIN_VALUE_DEFAULT_VALUE,
  .max_value = ZB_ZCL_TEMP_MEASUREMENT_MAX_VALUE_DEFAULT_VALUE,
#ifndef ZB_DISABLE_TEMP_MEASUREMENT_TOLERANCE_ID
  .tolerance = 0,
#endif
};
#endif /* CLI_HAS_CLUSTER_TEMPERATURE */


/* -----------------------------------------------------------------------------------
 *
 *                                  CLUSTER Pressure Measurement
 *
 * ----------------------------------------------------------------------------------- */


/* -----------------------------------------------------------------------------------
 *
 *                                  CLUSTER Flow Measurement
 *
 * ----------------------------------------------------------------------------------- */


/* -----------------------------------------------------------------------------------
 *
 *                                  CLUSTER Relative Humidity Measurement
 *
 * ----------------------------------------------------------------------------------- */


/* -----------------------------------------------------------------------------------
 *
 *                                  CLUSTER Occupancy Sensing
 *
 * ----------------------------------------------------------------------------------- */


/* -----------------------------------------------------------------------------------
 *
 *                                  CLUSTER Electrical Measurement
 *
 * ----------------------------------------------------------------------------------- */


#if defined CLI_HAS_CLUSTER_OTA_UPGRADE_SRV || defined CLI_HAS_CLUSTER_OTA_UPGRADE_CLT
/* -----------------------------------------------------------------------------------
 *
 *                                  CLUSTER OTA Upgrade
 *
 * ----------------------------------------------------------------------------------- */

/* Client config */
#define OTA_UPGRADE_DEFAULT_MANUFACTURER       0xFFFF
#define OTA_UPGRADE_DEFAULT_IMAGE_TYPE         0xFFFF

/* OTA Upgrade client cluster attributes */
typedef struct {
  /* UpgradeServerID attribute */
  zb_ieee_addr_t upgrade_server;
  /* FileOffset attribute */
  zb_uint32_t file_offset;
  /* CurrentFileVersion attribute (custom data) */
  zb_uint32_t file_version;
  /* CurrentZigbeeStackVersion attribute */
  zb_uint16_t stack_version;
  /* DownloadedFileVersion attribute */
  zb_uint32_t downloaded_file_ver;
  /* DownloadedZigbeeStackVersion attribute */
  zb_uint16_t downloaded_stack_ver;
  /* ImageUpgradeStatus attribute */
  zb_uint8_t image_status;
  /* Manufacturer ID attribute (custom data) */
  zb_uint16_t manufacturer;
  /* Image Type ID attribute (custom data) */
  zb_uint16_t image_type;
  /* MinimumBlockPeriod attribute */
  zb_uint16_t min_block_period;
  /* Image Stamp attribute */
  zb_uint16_t image_stamp;
} zb_zcl_general_ota_upgrade_attr_t;

static zb_zcl_general_ota_upgrade_attr_t g_general_ota_upgrade_attr = {
  .upgrade_server       = ZB_ZCL_OTA_UPGRADE_SERVER_DEF_VALUE,
  .file_offset          = ZB_ZCL_OTA_UPGRADE_FILE_OFFSET_DEF_VALUE,
  .file_version         = 0x00000000, /* Make sure own version is different from the server to get the file */
  .stack_version        = ZB_ZCL_OTA_UPGRADE_FILE_HEADER_STACK_PRO,
  .downloaded_file_ver  = ZB_ZCL_OTA_UPGRADE_DOWNLOADED_FILE_VERSION_DEF_VALUE,
  .downloaded_stack_ver = ZB_ZCL_OTA_UPGRADE_DOWNLOADED_STACK_DEF_VALUE,
  .image_status         = ZB_ZCL_OTA_UPGRADE_IMAGE_STATUS_DEF_VALUE,
  .manufacturer         = OTA_UPGRADE_DEFAULT_MANUFACTURER,
  .image_type           = OTA_UPGRADE_DEFAULT_IMAGE_TYPE,
  .min_block_period     = 0,
  .image_stamp          = ZB_ZCL_OTA_UPGRADE_IMAGE_STAMP_MIN_VALUE,
};

enum zb_zcl_nxp_ota_cmd_e
{
  ZB_ZCL_CMD_OTA_NXP_STATUS      = 0x00,  /* Status OTA NXP command identifier. */
  ZB_ZCL_CMD_OTA_NXP_GET_FILE    = 0x01,  /* Get file OTA NXP command identifier. */
  ZB_ZCL_CMD_OTA_NXP_ACCEPT_FILE = 0x02,  /* Accept File OTA NXP command identifier. */
#ifdef ZB_STACK_REGRESSION_TESTING_API
  ZB_ZCL_CMD_OTA_NXP_AUTO        = 0x03,  /* Auto OTA NXP command identifier. */
  ZB_ZCL_CMD_OTA_NXP_TEMPO       = 0x04,  /* Tempo OTA NXP command identifier. */
#endif
};
#endif /* CLI_HAS_CLUSTER_OTA_UPGRADE_SRV || CLI_HAS_CLUSTER_OTA_UPGRADE_CLT */


#ifdef CLI_HAS_CLUSTER_THERMOSTAT
/* -----------------------------------------------------------------------------------
 *
 *                                  CLUSTER Thermostat
 *
 * ----------------------------------------------------------------------------------- */

/* Thermostat cluster attributes */
typedef struct {
  zb_int16_t local_temperature;
  zb_int16_t occupied_cooling_setpoint;
  zb_int16_t occupied_heating_setpoint;
  zb_uint8_t control_seq_of_operation;
  zb_uint8_t system_mode;
} zb_zcl_general_thermostat_attr_t;

static zb_zcl_general_thermostat_attr_t g_general_thermostat_attr = {
  .local_temperature = ZB_ZCL_THERMOSTAT_LOCAL_TEMPERATURE_DEFAULT_VALUE,
  .occupied_cooling_setpoint = ZB_ZCL_THERMOSTAT_OCCUPIED_COOLING_SETPOINT_DEFAULT_VALUE,
  .occupied_heating_setpoint = ZB_ZCL_THERMOSTAT_OCCUPIED_HEATING_SETPOINT_DEFAULT_VALUE,
  .control_seq_of_operation  = ZB_ZCL_THERMOSTAT_CONTROL_SEQ_OF_OPERATION_DEFAULT_VALUE,
  .system_mode               = ZB_ZCL_THERMOSTAT_CONTROL_SYSTEM_MODE_DEFAULT_VALUE,
};
#endif /* CLI_HAS_CLUSTER_THERMOSTAT */


#ifdef CLI_HAS_CLUSTER_MANUF_SPE
/* -----------------------------------------------------------------------------------
 *
 *                                  CLUSTER NXP CUSTOM
 *
 * ----------------------------------------------------------------------------------- */

typedef zb_uint8_t zb_24bit_t[3];
typedef zb_uint8_t zb_40bit_t[5];
typedef zb_uint8_t zb_48bit_t[6];
typedef zb_uint8_t zb_56bit_t[7];
typedef zb_uint8_t zb_64bit_t[8];
typedef zb_uint8_t zb_128bit_t[16];
typedef struct {
  zb_uint8_t size; /* max size: 255! */
  zb_uint8_t data[256];
} zb_string_t;
typedef struct {
  zb_uint16_t size; /* max size: 255! */
  zb_uint8_t data[256];
} zb_long_string_t;
typedef struct { /* refer to zb_zcl_get_attribute_size() */
  zb_uint8_t       type_null;
  zb_uint8_t       type_8bit;
  zb_uint16_t      type_16bit;
  zb_24bit_t       type_24bit;
  zb_uint32_t      type_32bit;
  zb_40bit_t       type_40bit;
  zb_48bit_t       type_48bit;
  zb_56bit_t       type_56bit;
  zb_64bit_t       type_64bit;
  zb_bool_t        type_bool;
  zb_uint8_t       type_8bitmap;
  zb_uint16_t      type_16bitmap;
  zb_24bit_t       type_24bitmap;
  zb_uint32_t      type_32bitmap;
  zb_40bit_t       type_40bitmap;
  zb_48bit_t       type_48bitmap;
  zb_56bit_t       type_56bitmap;
  zb_64bit_t       type_64bitmap;
  zb_uint8_t       type_u8;
  zb_uint16_t      type_u16;
  zb_24bit_t       type_u24;
  zb_uint32_t      type_u32;
  zb_40bit_t       type_u40;
  zb_48bit_t       type_u48;
  zb_56bit_t       type_u56;
  zb_64bit_t       type_u64;
  zb_int8_t        type_s8;
  zb_int16_t       type_s16;
  zb_24bit_t       type_s24;
  zb_int32_t       type_s32;
  zb_40bit_t       type_s40;
  zb_48bit_t       type_s48;
  zb_56bit_t       type_s56;
  zb_64bit_t       type_s64;
  zb_uint8_t       type_8bit_enum;
  zb_uint16_t      type_16bit_enum;
  zb_uint16_t      type_semi;
  zb_uint32_t      type_single;
  zb_64bit_t       type_double;
  zb_string_t      type_octet_string;
  zb_string_t      type_char_string;
  zb_uint8_t       type_long_octet_string[256];
  zb_long_string_t type_long_char_string;
  zb_uint8_t       type_array[256];
  zb_uint8_t       type_custom_32array[256];
  zb_uint8_t       type_structure[256];
  zb_uint8_t       type_set[256];
  zb_uint8_t       type_bag[256];
  zb_uint32_t      type_time_of_day;
  zb_uint32_t      type_date;
  zb_uint32_t      type_utc_time;
  zb_uint16_t      type_cluster_id;
  zb_uint16_t      type_attribute_id;
  zb_uint32_t      type_bacnet_oid;
  zb_ieee_addr_t   type_ieee_addr;
  zb_128bit_t      type_128_bit_key;
} zb_zcl_custom_nxp_attr_access_t;

typedef struct {
  zb_zcl_custom_nxp_attr_access_t ro; /* read */
  zb_zcl_custom_nxp_attr_access_t ow; /*      write */
  zb_zcl_custom_nxp_attr_access_t rw; /* read write */
} zb_zcl_custom_nxp_attr_t;


static zb_zcl_custom_nxp_attr_t g_custom_nxp_attr = { 0 };

enum zb_zcl_nxp_custom_cmd_e
{
  ZB_ZCL_CMD_NXP_PING    = 0x01,  /* Payload NXP custom command ping identifier. */
  ZB_ZCL_CMD_NXP_ABORT   = 0x02,  /* Payload NXP custom command abort ongoing ping identifier. */
  ZB_ZCL_CMD_NXP_STATUS  = 0x03,  /* Payload NXP custom command status ongoing ping identifier. */
};
#endif /* CLI_HAS_CLUSTER_MANUF_SPE */
```

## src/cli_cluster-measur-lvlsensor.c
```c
/*
 * Copyright 2025 NXP
 *
 * NXP Proprietary.
 * This software is owned or controlled by NXP and may only be used strictly
 * in accordance with the applicable license terms. By expressly accepting
 * such terms or by downloading, installing, activating and/or otherwise using
 * the software, you are agreeing that you have read, and that you agree to
 * comply with and are bound by, such license terms. If you do not agree to be
 * bound by the applicable license terms, then you may not retain, install,
 * activate or otherwise use the software.
 *
 */


/* -----------------------------------------------------------------------------------
 *
 *                                  CLUSTER Illuminance Measurement
 *
 * ----------------------------------------------------------------------------------- */


/* -----------------------------------------------------------------------------------
 *
 *                                  CLUSTER Illuminance Level Sensing
 *
 * ----------------------------------------------------------------------------------- */


/* -----------------------------------------------------------------------------------
 *
 *                                  CLUSTER Temperature Measurement
 *
 * ----------------------------------------------------------------------------------- */
#ifndef CLI_HAS_CLUSTER_TEMPERATURE
#define pCluster_0402 NULL
#else
#define pCluster_0402 &cluster_0402

/* variable hidden  in macro ZB_ZCL_START_DECLARE_ATTRIB_LIST_CLUSTER_REVISION */
static zb_uint16_t cluster_revision_temp_measurement_attr_list = ZB_ZCL_TEMP_MEASUREMENT_CLUSTER_REVISION_DEFAULT;

/* This table is extracted from macro
 *   ZB_ZCL_DECLARE_TEMP_MEASUREMENT_ATTRIB_LIST(temp_measurement_attr_list, 
 *                                               &g_attr_temp_measurement_value, 
 *                                               &g_attr_temp_measurement_min_value, 
 *                                               &g_attr_temp_measurement_max_value, 
 *                                               &g_attr_temp_measurement_tolerance);
 * to have a better view of its content
 *     ZB_ZCL_START_DECLARE_ATTRIB_LIST_CLUSTER_REVISION(attr_list, ZB_ZCL_TEMP_MEASUREMENT)
 *     ZB_ZCL_SET_ATTR_DESC(ZB_ZCL_ATTR_TEMP_MEASUREMENT_VALUE_ID, &g_attr_temp_measurement_value)
 *     ZB_ZCL_SET_ATTR_DESC(ZB_ZCL_ATTR_TEMP_MEASUREMENT_MIN_VALUE_ID, &g_attr_temp_measurement_min_value)
 *     ZB_ZCL_SET_ATTR_DESC(ZB_ZCL_ATTR_TEMP_MEASUREMENT_MAX_VALUE_ID, &g_attr_temp_measurement_max_value)
 *     ZB_ZCL_SET_ATTR_DESC(ZB_ZCL_ATTR_TEMP_MEASUREMENT_TOLERANCE_ID, &g_attr_temp_measurement_tolerance)
 *     ZB_ZCL_FINISH_DECLARE_ATTRIB_LIST
 */

static zb_zcl_attr_t cluster_attr_0402[] = {
  /* Mandatory attributes */
  { ZB_ZCL_ATTR_GLOBAL_CLUSTER_REVISION_ID,    ZB_ZCL_ATTR_TYPE_U16, ACC_READ_ONLY,                 NO_MANUF_SPE, (void*)&cluster_revision_temp_measurement_attr_list },
  { ZB_ZCL_ATTR_TEMP_MEASUREMENT_VALUE_ID,     ZB_ZCL_ATTR_TYPE_S16, ACC_READ_ONLY | ACC_REPORTING, NO_MANUF_SPE, (void*)&g_lvlsensor_temp_measurement_attr.value },
  { ZB_ZCL_ATTR_TEMP_MEASUREMENT_MIN_VALUE_ID, ZB_ZCL_ATTR_TYPE_S16, ACC_READ_ONLY,                 NO_MANUF_SPE, (void*)&g_lvlsensor_temp_measurement_attr.min_value },
  { ZB_ZCL_ATTR_TEMP_MEASUREMENT_MAX_VALUE_ID, ZB_ZCL_ATTR_TYPE_S16, ACC_READ_ONLY,                 NO_MANUF_SPE, (void*)&g_lvlsensor_temp_measurement_attr.max_value },
#ifndef ZB_DISABLE_TEMP_MEASUREMENT_TOLERANCE_ID
  { ZB_ZCL_ATTR_TEMP_MEASUREMENT_TOLERANCE_ID, ZB_ZCL_ATTR_TYPE_U16, ACC_READ_ONLY,                 NO_MANUF_SPE, (void*)&g_lvlsensor_temp_measurement_attr.tolerance },
#endif
  /* Optional attributes */
  /* End of table */
  { ZB_ZCL_NULL_ID,                         0,                          0,             NO_MANUF_SPE, NULL }
};


static zb_cluster_def cluster_0402 = {
  cluster_attr_0402,
  sizeof(cluster_attr_0402)/sizeof(zb_zcl_attr_t),
  zb_zcl_temp_measurement_init_server,                          /* Can be replaced by our implementation to configure zb_zcl_cluster_write_attr_hook_t */
  zb_zcl_temp_measurement_init_client,                          /* Can be replaced by our implementation to configure zb_zcl_cluster_write_attr_hook_t */
  dummy_commands_handler,
};
#endif /* CLI_HAS_CLUSTER_TEMPERATURE */


/* -----------------------------------------------------------------------------------
 *
 *                                  CLUSTER Pressure Measurement
 *
 * ----------------------------------------------------------------------------------- */


/* -----------------------------------------------------------------------------------
 *
 *                                  CLUSTER Flow Measurement
 *
 * ----------------------------------------------------------------------------------- */


/* -----------------------------------------------------------------------------------
 *
 *                                  CLUSTER Relative Humidity Measurement
 *
 * ----------------------------------------------------------------------------------- */


/* -----------------------------------------------------------------------------------
 *
 *                                  CLUSTER Occupancy Sensing
 *
 * ----------------------------------------------------------------------------------- */


/* -----------------------------------------------------------------------------------
 *
 *                                  CLUSTER Electrical Measurement
 *
 * ----------------------------------------------------------------------------------- */
```

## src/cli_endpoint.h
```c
/*
 * Copyright 2024-2025 NXP
 *
 * NXP Proprietary.
 * This software is owned or controlled by NXP and may only be used strictly
 * in accordance with the applicable license terms. By expressly accepting
 * such terms or by downloading, installing, activating and/or otherwise using
 * the software, you are agreeing that you have read, and that you agree to
 * comply with and are bound by, such license terms. If you do not agree to be
 * bound by the applicable license terms, then you may not retain, install,
 * activate or otherwise use the software.
 *
 */

#ifndef CLI_NXP_ENDPOINT_H
#define CLI_NXP_ENDPOINT_H 1

#include "zboss_api.h"
#include "cli_menu.h"

#ifdef ZB_PLATFORM_LINUX
#define MAX_ENDPOINTS 256
#endif
#ifdef ZB_PLATFORM_ZEPHYR
#define MAX_ENDPOINTS 8
#endif

typedef struct {
  zb_uint16_t         id;
  char               *name;
  char               *initials;
  char               *align;
} zb_endpoint_profile;

typedef struct {
  zb_uint16_t  id;
  char        *group;
  char        *name;
  char        *initials;
  char        *align;
} zb_endpoint_device;

extern zb_endpoint_profile table_profiles[];
extern zb_endpoint_device endpoint_devices[];

void help_profiles(void);


extern cli_menu_cmd menu_endpoint[];

/* Context containing endpoints table, each endpoint containing clusters table */
extern zb_af_device_ctx_t cli_ctx;

zb_af_endpoint_desc_t *endpoint_get_by_id(zb_uint8_t ep_id);


#endif /* CLI_NXP_ENDPOINT_H */
```
